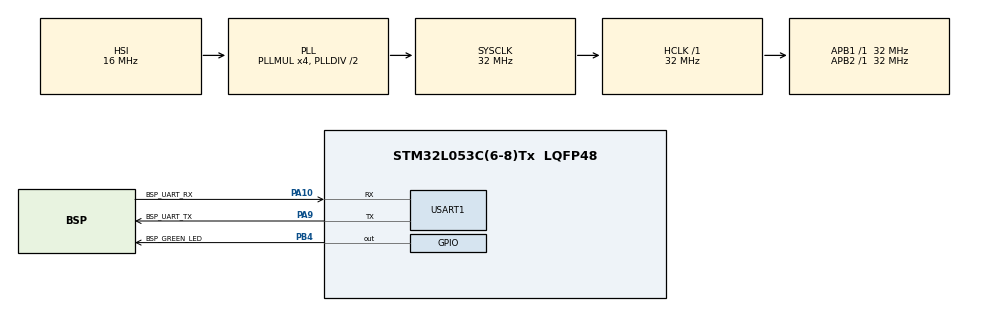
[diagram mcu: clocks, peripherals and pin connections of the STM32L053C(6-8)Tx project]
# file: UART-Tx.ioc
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Mcu.Family=STM32L0
Mcu.Name=STM32L053C(6-8)Tx
Mcu.Package=LQFP48
NVIC.USART1_IRQn=true\:0\:0\:false\:false\:true\:true\:true\:true
PA10.GPIO_Label=BSP_UART_RX
PA10.Mode=Asynchronous
PA10.Signal=USART1_RX
PA13.Mode=Serial_Wire
PA13.Signal=SYS_SWDIO
PA14.Mode=Serial_Wire
PA14.Signal=SYS_SWCLK
PA9.GPIO_Label=BSP_UART_TX
PA9.Mode=Asynchronous
PA9.Signal=USART1_TX
PB4.GPIO_Label=BSP_GREEN_LED
PB4.Signal=GPIO_Output
PC14-OSC32_IN.Mode=LSE-External-Oscillator
PC14-OSC32_IN.Signal=RCC_OSC32_IN
PC15-OSC32_OUT.Mode=LSE-External-Oscillator
PC15-OSC32_OUT.Signal=RCC_OSC32_OUT
PH0-OSC_IN.Mode=HSE-External-Oscillator
PH0-OSC_IN.Signal=RCC_OSC_IN
PH1-OSC_OUT.Mode=HSE-External-Oscillator
PH1-OSC_OUT.Signal=RCC_OSC_OUT
ProjectManager.HeapSize=0x200
ProjectManager.StackSize=0x400
ProjectManager.TargetToolchain=STM32CubeIDE
RCC.AHBFreq_Value=32000000
RCC.APB1Freq_Value=32000000
RCC.APB1TimFreq_Value=32000000
RCC.APB2Freq_Value=32000000
RCC.APB2TimFreq_Value=32000000
RCC.HCLKFreq_Value=32000000
RCC.HSE_VALUE=8000000
RCC.HSI16_VALUE=16000000
RCC.HSI48MClockSelection=RCC_USBCLKSOURCE_HSI48
RCC.HSI48_VALUE=48000000
RCC.HSI_VALUE=16000000
RCC.MSI_VALUE=2097000
RCC.PLLMUL=RCC_PLLMUL_4
RCC.RTCClockSelectionVirtual=RCC_RTCCLKSOURCE_LSE
RCC.SYSCLKFreq_VALUE=32000000
RCC.SYSCLKSource=RCC_SYSCLKSOURCE_PLLCLK
RCC.VCOOutputFreq_Value=64000000
USART1.StopBits=STOPBITS_1
USART1.VirtualMode-Asynchronous=VM_ASYNC
board=STM32L0538-DISCO

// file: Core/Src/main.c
/* USER CODE BEGIN Header */
/**
 ******************************************************************************
 * @file           : main.c
 * @brief          : Main program body
 ******************************************************************************
 * @attention
 *
 * Copyright (c) 2023 STMicroelectronics.
 * All rights reserved.
 *
 * This software is licensed under terms that can be found in the LICENSE file
 * in the root directory of this software component.
 * If no LICENSE file comes with this software, it is provided AS-IS.
 *
 ******************************************************************************
 */
/* USER CODE END Header */
#include "main.h"

/* USER CODE BEGIN Includes */
#include "stdio.h"
/* USER CODE END Includes */

UART_HandleTypeDef huart1;

/* USER CODE BEGIN PV */
uint8_t Tx_data[20] = "Hello UART...\r\n";
/* USER CODE END PV */

void SystemClock_Config(void);
static void MX_GPIO_Init(void);
static void MX_USART1_UART_Init(void);

int main(void)
{

  /* MCU Configuration--------------------------------------------------------*/

  /* Reset of all peripherals, Initializes the Flash interface and the Systick. */
  HAL_Init();

  /* Configure the system clock */
  SystemClock_Config();

  /* Initialize all configured peripherals */
  MX_GPIO_Init();
  MX_USART1_UART_Init();
  /* USER CODE BEGIN 2 */
	HAL_UART_Transmit_IT(&huart1, Tx_data, sizeof(Tx_data));
  /* USER CODE END 2 */

  /* Infinite loop */
	while (1) {

    /* USER CODE BEGIN 3 */
		printf("hello...\r\n");
		HAL_Delay(1000);
	}
  /* USER CODE END 3 */
}

void SystemClock_Config(void)
{
  RCC_OscInitTypeDef RCC_OscInitStruct = {0};
  RCC_ClkInitTypeDef RCC_ClkInitStruct = {0};
  RCC_PeriphCLKInitTypeDef PeriphClkInit = {0};

  /** Configure the main internal regulator output voltage
  */
  __HAL_PWR_VOLTAGESCALING_CONFIG(PWR_REGULATOR_VOLTAGE_SCALE1);

  /** Initializes the RCC Oscillators according to the specified parameters
  * in the RCC_OscInitTypeDef structure.
  */
  RCC_OscInitStruct.OscillatorType = RCC_OSCILLATORTYPE_HSI;
  RCC_OscInitStruct.HSIState = RCC_HSI_ON;
  RCC_OscInitStruct.HSICalibrationValue = RCC_HSICALIBRATION_DEFAULT;
  RCC_OscInitStruct.PLL.PLLState = RCC_PLL_ON;
  RCC_OscInitStruct.PLL.PLLSource = RCC_PLLSOURCE_HSI;
  RCC_OscInitStruct.PLL.PLLMUL = RCC_PLLMUL_4;
  RCC_OscInitStruct.PLL.PLLDIV = RCC_PLLDIV_2;
  if (HAL_RCC_OscConfig(&RCC_OscInitStruct) != HAL_OK)
  {
    Error_Handler();
  }

  /** Initializes the CPU, AHB and APB buses clocks
  */
  RCC_ClkInitStruct.ClockType = RCC_CLOCKTYPE_HCLK|RCC_CLOCKTYPE_SYSCLK
                              |RCC_CLOCKTYPE_PCLK1|RCC_CLOCKTYPE_PCLK2;
  RCC_ClkInitStruct.SYSCLKSource = RCC_SYSCLKSOURCE_PLLCLK;
  RCC_ClkInitStruct.AHBCLKDivider = RCC_SYSCLK_DIV1;
  RCC_ClkInitStruct.APB1CLKDivider = RCC_HCLK_DIV1;
  RCC_ClkInitStruct.APB2CLKDivider = RCC_HCLK_DIV1;

  if (HAL_RCC_ClockConfig(&RCC_ClkInitStruct, FLASH_LATENCY_1) != HAL_OK)
  {
    Error_Handler();
  }
  PeriphClkInit.PeriphClockSelection = RCC_PERIPHCLK_USART1;
  PeriphClkInit.Usart1ClockSelection = RCC_USART1CLKSOURCE_PCLK2;
  if (HAL_RCCEx_PeriphCLKConfig(&PeriphClkInit) != HAL_OK)
  {
    Error_Handler();
  }
}

static void MX_USART1_UART_Init(void)
{

  huart1.Instance = USART1;
  huart1.Init.BaudRate = 115200;
  huart1.Init.WordLength = UART_WORDLENGTH_8B;
  huart1.Init.StopBits = UART_STOPBITS_1;
  huart1.Init.Parity = UART_PARITY_NONE;
  huart1.Init.Mode = UART_MODE_TX_RX;
  huart1.Init.HwFlowCtl = UART_HWCONTROL_NONE;
  huart1.Init.OverSampling = UART_OVERSAMPLING_16;
  huart1.Init.OneBitSampling = UART_ONE_BIT_SAMPLE_DISABLE;
  huart1.AdvancedInit.AdvFeatureInit = UART_ADVFEATURE_NO_INIT;
  if (HAL_UART_Init(&huart1) != HAL_OK)
  {
    Error_Handler();
  }

}

static void MX_GPIO_Init(void)
{
  GPIO_InitTypeDef GPIO_InitStruct = {0};

  /* GPIO Ports Clock Enable */
  __HAL_RCC_GPIOC_CLK_ENABLE();
  __HAL_RCC_GPIOH_CLK_ENABLE();
  __HAL_RCC_GPIOA_CLK_ENABLE();
  __HAL_RCC_GPIOB_CLK_ENABLE();

  /*Configure GPIO pin Output Level */
  HAL_GPIO_WritePin(BSP_GREEN_LED_GPIO_Port, BSP_GREEN_LED_Pin, GPIO_PIN_RESET);

  /*Configure GPIO pin : BSP_GREEN_LED_Pin */
  GPIO_InitStruct.Pin = BSP_GREEN_LED_Pin;
  GPIO_InitStruct.Mode = GPIO_MODE_OUTPUT_PP;
  GPIO_InitStruct.Pull = GPIO_NOPULL;
  GPIO_InitStruct.Speed = GPIO_SPEED_FREQ_LOW;
  HAL_GPIO_Init(BSP_GREEN_LED_GPIO_Port, &GPIO_InitStruct);

}

/* USER CODE BEGIN 4 */
void HAL_UART_TxCpltCallback(UART_HandleTypeDef *huart) {
	HAL_GPIO_WritePin(BSP_GREEN_LED_GPIO_Port, BSP_GREEN_LED_Pin, GPIO_PIN_SET);
}
/* USER CODE END 4 */

void Error_Handler(void)
{
	__disable_irq();
	while (1) {
	}
}
